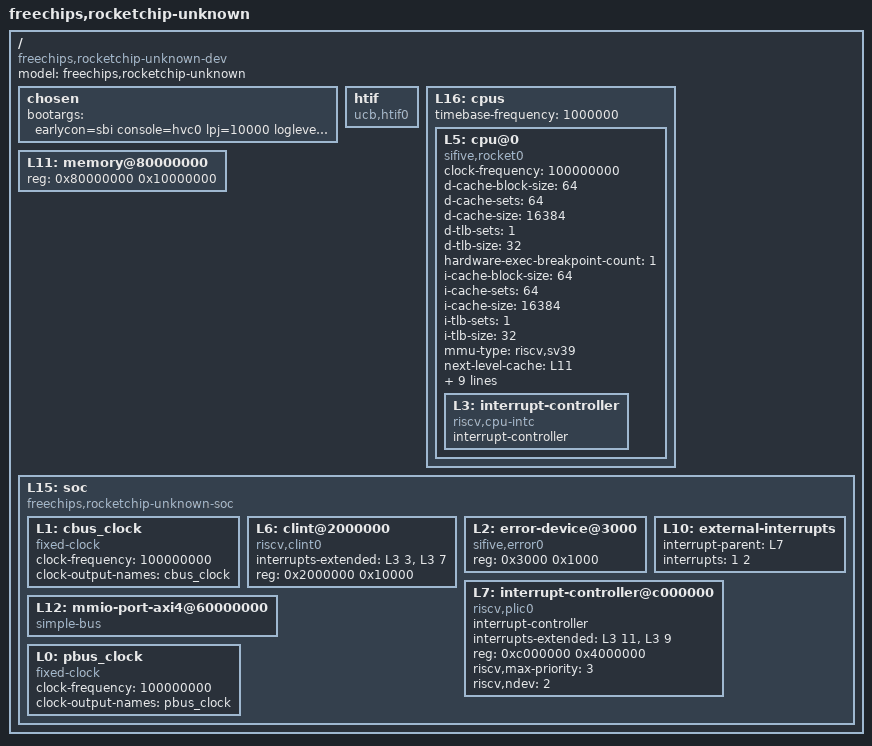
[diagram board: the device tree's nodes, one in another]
/dts-v1/;

/ {
	#address-cells = <1>;
	#size-cells = <1>;
	compatible = "freechips,rocketchip-unknown-dev";
	model = "freechips,rocketchip-unknown";

	chosen {
		bootargs = "earlycon=sbi console=hvc0 lpj=10000 loglevel=7 rdinit=/init";
	};

	htif {
		compatible = "ucb,htif0";
	};

	L16: cpus {
		#address-cells = <1>;
		#size-cells = <0>;
		timebase-frequency = <1000000>;
		L5: cpu@0 {
			clock-frequency = <100000000>;
			compatible = "sifive,rocket0", "riscv";
			d-cache-block-size = <64>;
			d-cache-sets = <64>;
			d-cache-size = <16384>;
			d-tlb-sets = <1>;
			d-tlb-size = <32>;
			device_type = "cpu";
			hardware-exec-breakpoint-count = <1>;
			i-cache-block-size = <64>;
			i-cache-sets = <64>;
			i-cache-size = <16384>;
			i-tlb-sets = <1>;
			i-tlb-size = <32>;
			mmu-type = "riscv,sv39";
			next-level-cache = <&L11>;
			reg = <0x0>;
			riscv,isa = "rv64imafdc";
			riscv,isa-base = "rv64i";
			riscv,isa-extensions = "i", "m", "a", "f", "d", "c", "zicsr", "zifencei", "zihpm";
			riscv,pmpgranularity = <4>;
			riscv,pmpregions = <8>;
			status = "okay";
			timebase-frequency = <1000000>;
			tlb-split;
			L3: interrupt-controller {
				#interrupt-cells = <1>;
				compatible = "riscv,cpu-intc";
				interrupt-controller;
			};
		};
	};

	L11: memory@80000000 {
		device_type = "memory";
		reg = <0x80000000 0x10000000>;
	};

	L15: soc {
		#address-cells = <1>;
		#size-cells = <1>;
		compatible = "freechips,rocketchip-unknown-soc", "simple-bus";
		ranges;
		L1: cbus_clock {
			#clock-cells = <0>;
			clock-frequency = <100000000>;
			clock-output-names = "cbus_clock";
			compatible = "fixed-clock";
		};
		L6: clint@2000000 {
			compatible = "riscv,clint0";
			interrupts-extended = <&L3 3 &L3 7>;
			reg = <0x2000000 0x10000>;
			reg-names = "control";
		};
		L2: error-device@3000 {
			compatible = "sifive,error0";
			reg = <0x3000 0x1000>;
		};
		L10: external-interrupts {
			interrupt-parent = <&L7>;
			interrupts = <1 2>;
		};
		L7: interrupt-controller@c000000 {
			#interrupt-cells = <1>;
			compatible = "riscv,plic0";
			interrupt-controller;
			interrupts-extended = <&L3 11 &L3 9>;
			reg = <0xc000000 0x4000000>;
			reg-names = "control";
			riscv,max-priority = <3>;
			riscv,ndev = <2>;
		};
		L12: mmio-port-axi4@60000000 {
			#address-cells = <1>;
			#size-cells = <1>;
			compatible = "simple-bus";
			ranges = <0x60000000 0x60000000 0x20000000>;
		};
		L0: pbus_clock {
			#clock-cells = <0>;
			clock-frequency = <100000000>;
			clock-output-names = "pbus_clock";
			compatible = "fixed-clock";
		};
	};
};
